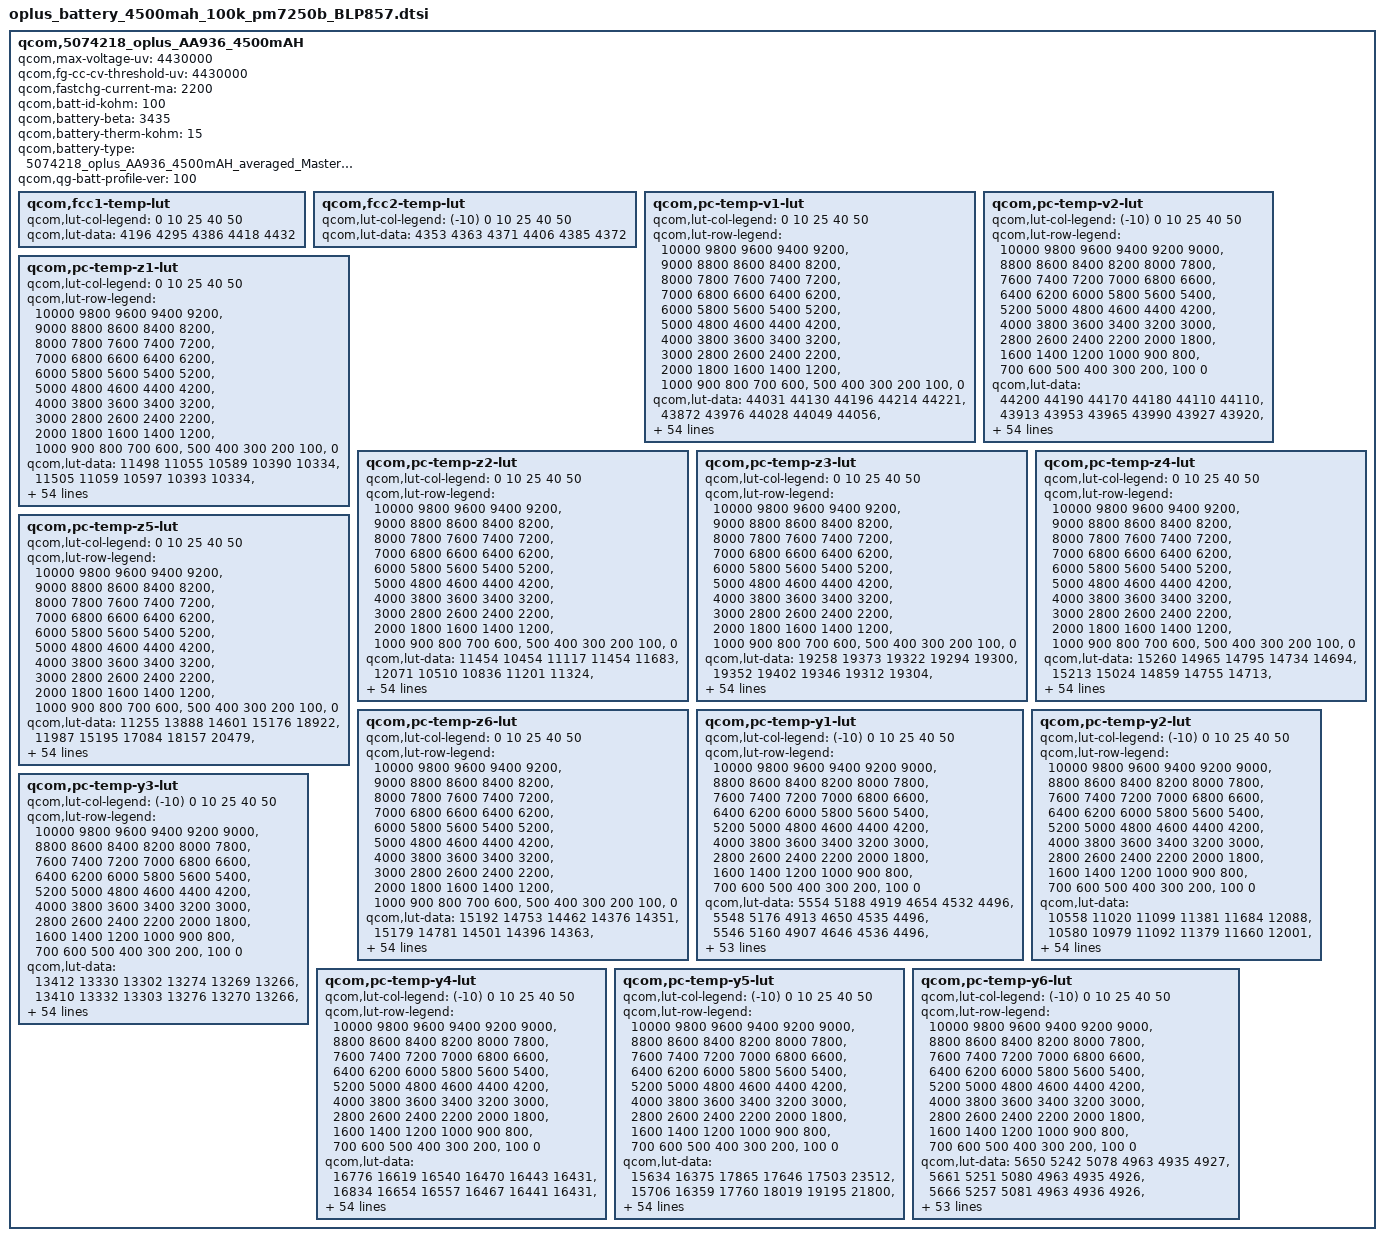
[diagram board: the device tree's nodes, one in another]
qcom,5074218_oplus_AA936_4500mAH {
    /* 5074218_oplus_AA936_4500mAH_averaged_MasterSlave_Mar5th2021 */
    qcom,max-voltage-uv = <4430000>;
    qcom,fg-cc-cv-threshold-uv = <4430000>;
    qcom,fastchg-current-ma = <2200>;
    qcom,batt-id-kohm = <100>;
    qcom,battery-beta = <3435>;
    qcom,battery-therm-kohm = <15>;
    qcom,battery-type = "5074218_oplus_AA936_4500mAH_averaged_MasterSlave_Mar5th2021";
    qcom,qg-batt-profile-ver = <100>;

	qcom,fcc1-temp-lut {
		qcom,lut-col-legend = <0 10 25 40 50>;
		qcom,lut-data = <4196 4295 4386 4418 4432>;
	};

	qcom,fcc2-temp-lut {
		qcom,lut-col-legend = <(-10) 0 10 25 40 50>;
		qcom,lut-data = <4353 4363 4371 4406 4385 4372>;
	};

	qcom,pc-temp-v1-lut {
		qcom,lut-col-legend = <0 10 25 40 50>;
		qcom,lut-row-legend = <10000 9800 9600 9400 9200>,
			<9000 8800 8600 8400 8200>,
			<8000 7800 7600 7400 7200>,
			<7000 6800 6600 6400 6200>,
			<6000 5800 5600 5400 5200>,
			<5000 4800 4600 4400 4200>,
			<4000 3800 3600 3400 3200>,
			<3000 2800 2600 2400 2200>,
			<2000 1800 1600 1400 1200>,
			<1000 900 800 700 600>,
			<500 400 300 200 100>,
			<0>;
		qcom,lut-data = <44031 44130 44196 44214 44221>,
			<43872 43976 44028 44049 44056>,
			<43684 43783 43848 43874 43882>,
			<43459 43580 43659 43688 43699>,
			<43216 43370 43459 43493 43507>,
			<42983 43150 43244 43285 43302>,
			<42753 42924 43017 43063 43084>,
			<42525 42691 42786 42835 42860>,
			<42300 42457 42549 42600 42629>,
			<42077 42224 42311 42361 42393>,
			<41858 41993 42075 42126 42159>,
			<41644 41767 41841 41891 41925>,
			<41433 41547 41614 41661 41695>,
			<41229 41334 41390 41434 41468>,
			<41031 41126 41173 41212 41244>,
			<40836 40924 40963 40997 41027>,
			<40643 40726 40759 40788 40815>,
			<40451 40541 40564 40587 40611>,
			<40246 40355 40385 40404 40425>,
			<40007 40132 40197 40220 40243>,
			<39765 39847 39961 40001 40031>,
			<39569 39584 39690 39737 39775>,
			<39400 39409 39462 39497 39534>,
			<39253 39270 39286 39310 39343>,
			<39131 39139 39133 39148 39176>,
			<39025 39010 38996 39005 39027>,
			<38928 38890 38873 38878 38895>,
			<38835 38782 38761 38762 38774>,
			<38748 38685 38656 38653 38661>,
			<38667 38595 38558 38552 38555>,
			<38593 38515 38469 38458 38457>,
			<38523 38443 38388 38371 38366>,
			<38463 38376 38314 38292 38282>,
			<38407 38314 38248 38221 38205>,
			<38356 38258 38188 38157 38134>,
			<38315 38208 38130 38088 38055>,
			<38273 38166 38078 38014 37961>,
			<38212 38112 38019 37933 37859>,
			<38115 38027 37937 37842 37758>,
			<37998 37918 37832 37740 37655>,
			<37874 37800 37718 37627 37541>,
			<37734 37665 37591 37499 37405>,
			<37565 37511 37449 37357 37258>,
			<37389 37334 37278 37188 37094>,
			<37294 37192 37145 37069 36982>,
			<37210 37121 37078 37011 36931>,
			<37179 37095 37060 36994 36915>,
			<37151 37076 37041 36978 36900>,
			<37108 37050 37007 36948 36863>,
			<36976 36932 36864 36764 36667>,
			<36619 36578 36485 36391 36294>,
			<36133 36103 36005 35907 35824>,
			<35518 35495 35385 35290 35215>,
			<34684 34674 34542 34447 34387>,
			<33359 33377 33219 33129 33105>,
			<30000 30000 30000 30000 30000>;
	};

	qcom,pc-temp-v2-lut {
		qcom,lut-col-legend = <(-10) 0 10 25 40 50>;
		qcom,lut-row-legend = <10000 9800 9600 9400 9200 9000>,
			<8800 8600 8400 8200 8000 7800>,
			<7600 7400 7200 7000 6800 6600>,
			<6400 6200 6000 5800 5600 5400>,
			<5200 5000 4800 4600 4400 4200>,
			<4000 3800 3600 3400 3200 3000>,
			<2800 2600 2400 2200 2000 1800>,
			<1600 1400 1200 1000 900 800>,
			<700 600 500 400 300 200>,
			<100 0>;
		qcom,lut-data = <44200 44190 44170 44180 44110 44110>,
			<43913 43953 43965 43990 43927 43920>,
			<43641 43723 43760 43795 43736 43725>,
			<43384 43500 43555 43596 43539 43525>,
			<43144 43287 43350 43393 43334 43320>,
			<42907 43071 43139 43183 43121 43108>,
			<42664 42844 42916 42958 42896 42886>,
			<42420 42609 42684 42722 42662 42655>,
			<42180 42376 42451 42487 42429 42424>,
			<41948 42141 42213 42249 42193 42189>,
			<41719 41909 41977 42012 41959 41956>,
			<41489 41680 41746 41778 41728 41726>,
			<41258 41455 41520 41547 41500 41498>,
			<41047 41237 41297 41321 41276 41275>,
			<40878 41026 41077 41100 41057 41057>,
			<40712 40822 40862 40886 40844 40845>,
			<40483 40621 40656 40679 40640 40641>,
			<40164 40428 40460 40478 40443 40446>,
			<39851 40217 40252 40275 40244 40249>,
			<39597 39943 40002 40067 40035 40043>,
			<39366 39641 39736 39851 39820 39832>,
			<39155 39389 39497 39614 39593 39610>,
			<38960 39175 39273 39348 39343 39364>,
			<38783 38989 39076 39125 39126 39145>,
			<38621 38829 38918 38966 38970 38987>,
			<38473 38688 38782 38835 38842 38857>,
			<38352 38560 38656 38710 38721 38736>,
			<38255 38445 38538 38595 38607 38620>,
			<38173 38337 38428 38487 38501 38513>,
			<38105 38234 38326 38386 38401 38412>,
			<38047 38136 38231 38292 38309 38318>,
			<37993 38049 38143 38206 38223 38230>,
			<37942 37975 38060 38130 38148 38155>,
			<37891 37910 37981 38054 38072 38078>,
			<37837 37859 37908 37970 37973 37972>,
			<37782 37819 37842 37882 37855 37827>,
			<37719 37775 37772 37788 37739 37688>,
			<37643 37714 37693 37685 37631 37575>,
			<37555 37639 37608 37580 37528 37471>,
			<37456 37548 37515 37483 37424 37365>,
			<37342 37434 37413 37389 37324 37265>,
			<37215 37300 37298 37282 37214 37155>,
			<37069 37141 37148 37136 37059 37002>,
			<36908 36969 36994 37010 36922 36851>,
			<36798 36866 36916 36925 36873 36800>,
			<36714 36792 36862 36886 36839 36769>,
			<36676 36762 36839 36870 36821 36754>,
			<36631 36724 36807 36841 36793 36729>,
			<36556 36653 36739 36782 36712 36653>,
			<36363 36474 36555 36580 36457 36412>,
			<36001 36102 36158 36165 36024 35989>,
			<35488 35575 35630 35628 35473 35461>,
			<34808 34891 34944 34931 34747 34772>,
			<33870 33943 34012 33971 33699 33831>,
			<32379 32444 32627 32503 32554 32456>,
			<29037 29258 29610 29012 29009 29565>;
	};

	qcom,pc-temp-z1-lut {
		qcom,lut-col-legend = <0 10 25 40 50>;
		qcom,lut-row-legend = <10000 9800 9600 9400 9200>,
			<9000 8800 8600 8400 8200>,
			<8000 7800 7600 7400 7200>,
			<7000 6800 6600 6400 6200>,
			<6000 5800 5600 5400 5200>,
			<5000 4800 4600 4400 4200>,
			<4000 3800 3600 3400 3200>,
			<3000 2800 2600 2400 2200>,
			<2000 1800 1600 1400 1200>,
			<1000 900 800 700 600>,
			<500 400 300 200 100>,
			<0>;
		qcom,lut-data = <11498 11055 10589 10390 10334>,
			<11505 11059 10597 10393 10334>,
			<11503 11038 10594 10393 10335>,
			<11484 11024 10583 10389 10334>,
			<11457 11019 10572 10385 10334>,
			<11436 11015 10561 10383 10334>,
			<11414 11005 10551 10380 10332>,
			<11396 10981 10545 10378 10331>,
			<11384 10959 10541 10376 10330>,
			<11374 10943 10538 10374 10329>,
			<11364 10926 10534 10372 10329>,
			<11340 10921 10531 10371 10328>,
			<11315 10923 10529 10370 10327>,
			<11312 10925 10526 10369 10327>,
			<11323 10925 10524 10368 10327>,
			<11330 10924 10523 10368 10327>,
			<11327 10922 10521 10368 10327>,
			<11320 10919 10521 10368 10327>,
			<11317 10915 10520 10368 10328>,
			<11311 10911 10520 10367 10328>,
			<11302 10903 10521 10367 10328>,
			<11299 10898 10522 10368 10329>,
			<11299 10901 10524 10369 10330>,
			<11301 10910 10525 10371 10331>,
			<11306 10917 10527 10372 10333>,
			<11312 10921 10530 10374 10334>,
			<11316 10925 10535 10375 10335>,
			<11318 10924 10539 10377 10336>,
			<11320 10920 10543 10379 10338>,
			<11317 10918 10546 10381 10339>,
			<11310 10922 10549 10384 10341>,
			<11304 10929 10551 10386 10342>,
			<11309 10932 10554 10389 10343>,
			<11325 10933 10560 10392 10345>,
			<11338 10934 10568 10395 10347>,
			<11346 10938 10574 10398 10350>,
			<11356 10949 10578 10402 10352>,
			<11363 10957 10582 10405 10353>,
			<11367 10961 10586 10407 10355>,
			<11370 10965 10591 10409 10356>,
			<11377 10971 10594 10410 10357>,
			<11386 10980 10595 10412 10358>,
			<11398 10987 10597 10413 10358>,
			<11417 11000 10602 10413 10359>,
			<11402 11000 10609 10414 10359>,
			<11395 11005 10607 10415 10360>,
			<11396 10997 10614 10416 10360>,
			<11394 10993 10614 10417 10360>,
			<11397 10999 10616 10418 10361>,
			<11401 11015 10626 10421 10362>,
			<11402 11023 10631 10422 10363>,
			<11420 11020 10631 10425 10366>,
			<11440 11049 10641 10429 10369>,
			<11454 11045 10643 10433 10371>,
			<11454 11045 10643 10433 10371>,
			<11454 11045 10643 10433 10371>;
	};

	qcom,pc-temp-z2-lut {
		qcom,lut-col-legend = <0 10 25 40 50>;
		qcom,lut-row-legend = <10000 9800 9600 9400 9200>,
			<9000 8800 8600 8400 8200>,
			<8000 7800 7600 7400 7200>,
			<7000 6800 6600 6400 6200>,
			<6000 5800 5600 5400 5200>,
			<5000 4800 4600 4400 4200>,
			<4000 3800 3600 3400 3200>,
			<3000 2800 2600 2400 2200>,
			<2000 1800 1600 1400 1200>,
			<1000 900 800 700 600>,
			<500 400 300 200 100>,
			<0>;
		qcom,lut-data = <11454 10454 11117 11454 11683>,
			<12071 10510 10836 11201 11324>,
			<12190 10523 10800 11046 11159>,
			<11438 10527 10802 10941 11109>,
			<10529 10516 10799 10881 11080>,
			<10351 10498 10762 10871 11068>,
			<10332 10477 10721 10865 11061>,
			<10320 10450 10716 10866 11059>,
			<10308 10433 10722 10903 11075>,
			<10297 10443 10727 10940 11094>,
			<10294 10466 10728 10937 11092>,
			<10304 10476 10731 10920 11083>,
			<10321 10477 10737 10912 11081>,
			<10334 10478 10746 10935 11103>,
			<10346 10480 10753 10963 11131>,
			<10357 10485 10755 10963 11134>,
			<10364 10491 10756 10949 11134>,
			<10370 10497 10753 10942 11140>,
			<10379 10503 10747 10954 11186>,
			<10403 10503 10743 10972 11252>,
			<10428 10493 10749 10982 11261>,
			<10426 10485 10768 10995 11205>,
			<10382 10494 10788 11002 11130>,
			<10346 10519 10815 10927 11023>,
			<10350 10529 10839 10800 10893>,
			<10364 10523 10825 10764 10856>,
			<10371 10515 10765 10758 10855>,
			<10370 10512 10727 10758 10858>,
			<10368 10506 10722 10779 10883>,
			<10369 10502 10722 10824 10940>,
			<10382 10509 10728 10856 10988>,
			<10397 10525 10751 10875 11032>,
			<10406 10541 10778 10895 11083>,
			<10413 10557 10810 10933 11150>,
			<10418 10570 10845 10986 11231>,
			<10420 10571 10863 11025 11294>,
			<10421 10571 10872 11049 11346>,
			<10425 10571 10881 11072 11379>,
			<10440 10588 10913 11107 11371>,
			<10453 10611 10966 11150 11329>,
			<10443 10610 10983 11166 11288>,
			<10416 10579 10940 11127 11254>,
			<10414 10570 10903 11092 11216>,
			<10428 10581 10887 11093 11163>,
			<10581 10652 10912 11100 11159>,
			<16059 10636 10876 11049 11222>,
			<17859 10621 10851 11117 11237>,
			<19549 10621 10867 11154 11338>,
			<19078 10630 10847 11182 11456>,
			<17840 10688 10889 10971 11065>,
			<16435 10733 10815 10859 10996>,
			<16866 10722 10750 10817 10927>,
			<15900 10683 10721 10782 10851>,
			<14515 10805 10649 10723 10782>,
			<14515 10805 10649 10723 10782>,
			<14515 10805 10649 10723 10782>;
	};

	qcom,pc-temp-z3-lut {
		qcom,lut-col-legend = <0 10 25 40 50>;
		qcom,lut-row-legend = <10000 9800 9600 9400 9200>,
			<9000 8800 8600 8400 8200>,
			<8000 7800 7600 7400 7200>,
			<7000 6800 6600 6400 6200>,
			<6000 5800 5600 5400 5200>,
			<5000 4800 4600 4400 4200>,
			<4000 3800 3600 3400 3200>,
			<3000 2800 2600 2400 2200>,
			<2000 1800 1600 1400 1200>,
			<1000 900 800 700 600>,
			<500 400 300 200 100>,
			<0>;
		qcom,lut-data = <19258 19373 19322 19294 19300>,
			<19352 19402 19346 19312 19304>,
			<19431 19441 19360 19322 19308>,
			<19508 19464 19370 19328 19314>,
			<19567 19474 19376 19331 19318>,
			<19584 19480 19381 19332 19318>,
			<19592 19481 19384 19332 19317>,
			<19595 19482 19383 19331 19316>,
			<19594 19482 19378 19331 19315>,
			<19590 19479 19373 19330 19314>,
			<19585 19473 19370 19328 19312>,
			<19578 19468 19367 19326 19309>,
			<19571 19463 19365 19324 19307>,
			<19566 19459 19361 19321 19306>,
			<19561 19456 19358 19319 19305>,
			<19559 19454 19356 19318 19304>,
			<19558 19452 19354 19316 19304>,
			<19558 19449 19353 19315 19304>,
			<19558 19446 19352 19313 19300>,
			<19567 19447 19351 19312 19295>,
			<19579 19457 19350 19313 19296>,
			<19579 19466 19349 19319 19310>,
			<19567 19462 19350 19327 19321>,
			<19557 19450 19365 19333 19321>,
			<19558 19445 19383 19339 19320>,
			<19563 19458 19386 19340 19319>,
			<19565 19474 19386 19339 19317>,
			<19563 19476 19386 19337 19316>,
			<19561 19471 19382 19335 19314>,
			<19558 19465 19376 19332 19312>,
			<19555 19460 19372 19328 19310>,
			<19551 19455 19367 19325 19307>,
			<19548 19452 19364 19322 19305>,
			<19545 19450 19362 19319 19302>,
			<19543 19449 19361 19316 19299>,
			<19541 19449 19361 19316 19298>,
			<19539 19448 19360 19317 19301>,
			<19536 19448 19360 19318 19305>,
			<19531 19443 19360 19320 19307>,
			<19526 19436 19359 19324 19308>,
			<19522 19433 19358 19325 19309>,
			<19518 19431 19355 19323 19310>,
			<19514 19428 19353 19322 19310>,
			<19507 19423 19348 19324 19311>,
			<19271 19409 19342 19318 19309>,
			<19258 19401 19338 19311 19298>,
			<19257 19402 19333 19310 19294>,
			<19256 19399 19333 19306 19291>,
			<19256 19390 19333 19302 19292>,
			<19257 19386 19340 19320 19302>,
			<19257 19380 19349 19319 19304>,
			<19257 19377 19350 19323 19303>,
			<19257 19374 19353 19322 19304>,
			<19257 19339 19354 19323 19305>,
			<19257 19339 19354 19323 19305>,
			<19257 19339 19354 19323 19305>;
	};

	qcom,pc-temp-z4-lut {
		qcom,lut-col-legend = <0 10 25 40 50>;
		qcom,lut-row-legend = <10000 9800 9600 9400 9200>,
			<9000 8800 8600 8400 8200>,
			<8000 7800 7600 7400 7200>,
			<7000 6800 6600 6400 6200>,
			<6000 5800 5600 5400 5200>,
			<5000 4800 4600 4400 4200>,
			<4000 3800 3600 3400 3200>,
			<3000 2800 2600 2400 2200>,
			<2000 1800 1600 1400 1200>,
			<1000 900 800 700 600>,
			<500 400 300 200 100>,
			<0>;
		qcom,lut-data = <15260 14965 14795 14734 14694>,
			<15213 15024 14859 14755 14713>,
			<15172 15015 14855 14758 14718>,
			<15138 15000 14821 14742 14706>,
			<15104 14955 14788 14722 14689>,
			<15056 14891 14761 14706 14678>,
			<14989 14845 14737 14691 14667>,
			<14926 14807 14721 14681 14660>,
			<14883 14778 14710 14675 14656>,
			<14846 14758 14701 14670 14653>,
			<14817 14743 14695 14666 14650>,
			<14790 14736 14689 14661 14648>,
			<14770 14733 14685 14658 14645>,
			<14765 14731 14681 14653 14641>,
			<14763 14729 14677 14649 14637>,
			<14762 14726 14673 14645 14632>,
			<14764 14724 14670 14640 14627>,
			<14772 14726 14668 14637 14623>,
			<14784 14731 14667 14635 14623>,
			<14808 14744 14666 14634 14623>,
			<14837 14794 14690 14642 14626>,
			<14853 14836 14753 14681 14647>,
			<14867 14837 14780 14706 14663>,
			<14875 14834 14763 14701 14663>,
			<14867 14829 14738 14690 14662>,
			<14842 14803 14722 14682 14661>,
			<14823 14771 14709 14675 14657>,
			<14812 14761 14701 14669 14652>,
			<14805 14756 14696 14663 14647>,
			<14803 14754 14692 14659 14643>,
			<14803 14754 14691 14656 14640>,
			<14803 14753 14689 14653 14637>,
			<14803 14754 14689 14651 14635>,
			<14804 14756 14690 14651 14634>,
			<14804 14758 14692 14651 14633>,
			<14800 14758 14695 14652 14633>,
			<14793 14757 14700 14662 14641>,
			<14788 14755 14704 14672 14649>,
			<14783 14753 14704 14672 14649>,
			<14778 14748 14703 14668 14645>,
			<14766 14739 14702 14663 14642>,
			<14745 14722 14691 14657 14639>,
			<14725 14707 14680 14652 14637>,
			<14710 14694 14675 14648 14636>,
			<14879 14666 14659 14642 14628>,
			<14878 14648 14644 14633 14624>,
			<14872 14639 14636 14624 14618>,
			<14868 14636 14627 14619 14613>,
			<14865 14640 14625 14618 14610>,
			<14866 14648 14629 14616 14613>,
			<14870 14659 14622 14617 14615>,
			<14870 14661 14621 14615 14614>,
			<14873 14664 14619 14616 14614>,
			<14875 14704 14619 14616 14613>,
			<14875 14704 14619 14616 14613>,
			<14875 14704 14619 14616 14613>;
	};

	qcom,pc-temp-z5-lut {
		qcom,lut-col-legend = <0 10 25 40 50>;
		qcom,lut-row-legend = <10000 9800 9600 9400 9200>,
			<9000 8800 8600 8400 8200>,
			<8000 7800 7600 7400 7200>,
			<7000 6800 6600 6400 6200>,
			<6000 5800 5600 5400 5200>,
			<5000 4800 4600 4400 4200>,
			<4000 3800 3600 3400 3200>,
			<3000 2800 2600 2400 2200>,
			<2000 1800 1600 1400 1200>,
			<1000 900 800 700 600>,
			<500 400 300 200 100>,
			<0>;
		qcom,lut-data = <11255 13888 14601 15176 18922>,
			<11987 15195 17084 18157 20479>,
			<13299 17281 18149 19438 21673>,
			<15796 18924 18754 19837 22558>,
			<18715 19951 19293 20134 23280>,
			<20766 20842 20087 20577 23941>,
			<22330 21927 20848 21131 24555>,
			<23773 23217 21239 21658 25000>,
			<25196 24545 21718 22177 25327>,
			<26580 26046 21997 22620 25555>,
			<28142 27518 22286 22876 25462>,
			<30279 27971 22724 22993 24809>,
			<32273 27843 22856 23034 24429>,
			<33177 27687 22865 23093 24801>,
			<33564 27874 22910 23263 25588>,
			<34038 28614 23204 23753 27053>,
			<35460 29053 23794 24777 30274>,
			<37946 28865 24379 25627 32195>,
			<40007 28563 25097 26209 30715>,
			<41680 28894 25600 26638 27917>,
			<42925 32160 24393 25904 26137>,
			<42102 35081 21063 21989 24849>,
			<35861 32386 19642 19400 23669>,
			<30625 25129 20149 19629 22323>,
			<30800 21970 21099 20202 21062>,
			<32091 24993 22381 20948 20824>,
			<33493 29504 24385 22214 21589>,
			<35207 32227 26269 23584 22711>,
			<37193 34211 27718 24753 23915>,
			<38850 35647 29046 25917 25370>,
			<40433 36532 30370 27110 26708>,
			<41507 37200 31711 28403 28004>,
			<41816 37976 33068 29621 29074>,
			<41994 39068 34870 30755 29782>,
			<42054 39866 36692 31796 30340>,
			<41965 39945 37079 32027 30464>,
			<41787 39920 36435 30752 29438>,
			<41590 39833 35431 29440 28311>,
			<41285 38011 33992 29706 29050>,
			<40878 35402 32040 30834 32163>,
			<40234 34658 30871 31536 35226>,
			<39429 34640 30343 31649 38191>,
			<39684 34406 29864 31717 39666>,
			<40649 33397 26720 31903 38422>,
			<12724 37635 27436 28384 35259>,
			<11484 36636 30001 26928 25936>,
			<11407 40996 30121 32822 27431>,
			<11364 39265 35122 37309 32321>,
			<11369 28849 35350 32135 37563>,
			<11395 25471 30919 48674 42207>,
			<11402 21113 37695 40848 42573>,
			<11357 19868 37344 48817 38026>,
			<11309 18934 40980 44622 37177>,
			<11262 14302 39515 43387 36663>,
			<11262 14302 39515 43387 36663>,
			<11262 14302 39515 43387 36663>;
	};

	qcom,pc-temp-z6-lut {
		qcom,lut-col-legend = <0 10 25 40 50>;
		qcom,lut-row-legend = <10000 9800 9600 9400 9200>,
			<9000 8800 8600 8400 8200>,
			<8000 7800 7600 7400 7200>,
			<7000 6800 6600 6400 6200>,
			<6000 5800 5600 5400 5200>,
			<5000 4800 4600 4400 4200>,
			<4000 3800 3600 3400 3200>,
			<3000 2800 2600 2400 2200>,
			<2000 1800 1600 1400 1200>,
			<1000 900 800 700 600>,
			<500 400 300 200 100>,
			<0>;
		qcom,lut-data = <15192 14753 14462 14376 14351>,
			<15179 14781 14501 14396 14363>,
			<15164 14781 14501 14401 14367>,
			<15148 14778 14490 14397 14365>,
			<15127 14753 14479 14391 14361>,
			<15094 14714 14468 14384 14356>,
			<15039 14685 14458 14377 14351>,
			<14984 14659 14448 14372 14347>,
			<14942 14637 14439 14369 14344>,
			<14905 14621 14432 14366 14342>,
			<14874 14608 14427 14363 14340>,
			<14845 14599 14422 14359 14337>,
			<14823 14593 14418 14356 14335>,
			<14814 14588 14414 14353 14332>,
			<14809 14585 14411 14349 14330>,
			<14807 14581 14408 14347 14327>,
			<14807 14579 14405 14344 14325>,
			<14808 14578 14403 14342 14323>,
			<14810 14577 14402 14340 14320>,
			<14822 14580 14401 14339 14318>,
			<14839 14607 14411 14343 14320>,
			<14844 14630 14439 14365 14338>,
			<14845 14630 14450 14379 14351>,
			<14844 14624 14450 14379 14351>,
			<14841 14620 14450 14378 14351>,
			<14835 14616 14449 14377 14350>,
			<14830 14613 14444 14374 14347>,
			<14826 14609 14439 14370 14344>,
			<14823 14606 14435 14366 14342>,
			<14823 14603 14431 14363 14339>,
			<14823 14602 14429 14360 14336>,
			<14823 14601 14426 14357 14334>,
			<14823 14600 14425 14355 14331>,
			<14825 14602 14425 14354 14329>,
			<14826 14605 14427 14353 14327>,
			<14828 14607 14428 14353 14327>,
			<14829 14610 14432 14358 14333>,
			<14831 14611 14435 14364 14338>,
			<14834 14611 14435 14364 14339>,
			<14836 14610 14435 14365 14338>,
			<14835 14608 14435 14365 14338>,
			<14833 14603 14430 14361 14337>,
			<14833 14600 14425 14358 14336>,
			<14835 14597 14421 14358 14337>,
			<14805 14585 14412 14353 14333>,
			<14802 14575 14404 14345 14325>,
			<14801 14574 14399 14340 14320>,
			<14802 14572 14396 14336 14316>,
			<14807 14572 14396 14334 14315>,
			<14815 14579 14402 14344 14323>,
			<14823 14585 14406 14344 14325>,
			<14830 14588 14407 14346 14325>,
			<14839 14593 14409 14347 14326>,
			<14853 14598 14411 14348 14327>,
			<14853 14598 14411 14348 14327>,
			<14853 14598 14411 14348 14327>;
	};

	qcom,pc-temp-y1-lut {
		qcom,lut-col-legend = <(-10) 0 10 25 40 50>;
		qcom,lut-row-legend = <10000 9800 9600 9400 9200 9000>,
			<8800 8600 8400 8200 8000 7800>,
			<7600 7400 7200 7000 6800 6600>,
			<6400 6200 6000 5800 5600 5400>,
			<5200 5000 4800 4600 4400 4200>,
			<4000 3800 3600 3400 3200 3000>,
			<2800 2600 2400 2200 2000 1800>,
			<1600 1400 1200 1000 900 800>,
			<700 600 500 400 300 200>,
			<100 0>;
		qcom,lut-data = <5554 5188 4919 4654 4532 4496>,
			<5548 5176 4913 4650 4535 4496>,
			<5546 5160 4907 4646 4536 4496>,
			<5546 5144 4901 4643 4536 4496>,
			<5548 5131 4895 4639 4535 4496>,
			<5549 5125 4891 4636 4534 4496>,
			<5550 5126 4887 4632 4531 4496>,
			<5554 5130 4884 4629 4527 4496>,
			<5554 5131 4881 4626 4524 4496>,
			<5553 5129 4877 4621 4522 4495>,
			<5552 5126 4872 4617 4521 4493>,
			<5550 5125 4869 4615 4519 4493>,
			<5546 5122 4865 4613 4518 4493>,
			<5544 5121 4863 4612 4517 4493>,
			<5543 5122 4860 4611 4516 4493>,
			<5542 5122 4857 4610 4516 4492>,
			<5543 5121 4856 4609 4515 4491>,
			<5545 5119 4855 4608 4515 4491>,
			<5547 5118 4855 4608 4514 4490>,
			<5547 5121 4855 4608 4514 4490>,
			<5547 5125 4854 4608 4514 4489>,
			<5548 5125 4854 4608 4514 4489>,
			<5554 5123 4855 4609 4513 4490>,
			<5560 5120 4856 4611 4513 4492>,
			<5559 5119 4856 4612 4514 4492>,
			<5557 5118 4857 4614 4517 4493>,
			<5555 5118 4858 4615 4518 4493>,
			<5554 5124 4861 4616 4518 4493>,
			<5553 5132 4864 4617 4517 4493>,
			<5553 5133 4864 4620 4518 4493>,
			<5552 5133 4865 4623 4519 4494>,
			<5552 5133 4865 4625 4520 4494>,
			<5552 5133 4868 4626 4521 4496>,
			<5550 5134 4873 4627 4523 4498>,
			<5546 5134 4875 4629 4525 4499>,
			<5540 5135 4876 4631 4527 4499>,
			<5535 5137 4878 4634 4529 4499>,
			<5534 5142 4879 4637 4530 4500>,
			<5534 5151 4881 4640 4531 4502>,
			<5535 5154 4882 4642 4532 4503>,
			<5533 5148 4883 4643 4533 4502>,
			<5532 5142 4884 4645 4534 4501>,
			<5534 5143 4887 4647 4534 4502>,
			<5542 5147 4892 4648 4535 4504>,
			<5548 5149 4897 4650 4535 4505>,
			<5552 5151 4902 4653 4536 4505>,
			<5549 5157 4905 4654 4536 4506>,
			<5543 5159 4902 4652 4538 4507>,
			<5540 5155 4904 4655 4538 4507>,
			<5555 5156 4915 4653 4538 4506>,
			<5556 5155 4913 4655 4539 4507>,
			<5563 5150 4919 4658 4541 4510>,
			<5574 5162 4924 4662 4542 4508>,
			<5592 5161 4941 4664 4544 4512>,
			<5592 5161 4941 4664 4544 4512>,
			<5592 5161 4941 4664 4544 4512>;
	};

	qcom,pc-temp-y2-lut {
		qcom,lut-col-legend = <(-10) 0 10 25 40 50>;
		qcom,lut-row-legend = <10000 9800 9600 9400 9200 9000>,
			<8800 8600 8400 8200 8000 7800>,
			<7600 7400 7200 7000 6800 6600>,
			<6400 6200 6000 5800 5600 5400>,
			<5200 5000 4800 4600 4400 4200>,
			<4000 3800 3600 3400 3200 3000>,
			<2800 2600 2400 2200 2000 1800>,
			<1600 1400 1200 1000 900 800>,
			<700 600 500 400 300 200>,
			<100 0>;
		qcom,lut-data = <10558 11020 11099 11381 11684 12088>,
			<10580 10979 11092 11379 11660 12001>,
			<10607 10931 11081 11377 11626 11906>,
			<10634 10885 11069 11376 11590 11815>,
			<10655 10850 11057 11375 11558 11737>,
			<10666 10833 11048 11374 11537 11682>,
			<10664 10837 11039 11375 11529 11650>,
			<10660 10849 11030 11376 11522 11627>,
			<10659 10857 11028 11375 11510 11612>,
			<10671 10859 11037 11367 11474 11588>,
			<10690 10860 11046 11361 11441 11565>,
			<10708 10866 11047 11349 11442 11559>,
			<10732 10875 11045 11321 11468 11564>,
			<10757 10889 11045 11306 11481 11568>,
			<10804 10919 11051 11303 11475 11561>,
			<10851 10961 11064 11302 11469 11546>,
			<10852 11008 11091 11314 11476 11534>,
			<10815 11071 11158 11351 11496 11524>,
			<10784 11106 11197 11372 11517 11520>,
			<10776 11072 11177 11395 11533 11528>,
			<10772 11012 11143 11424 11552 11557>,
			<10771 10997 11139 11443 11582 11633>,
			<10776 11006 11171 11490 11641 11871>,
			<10780 11019 11205 11522 11703 12050>,
			<10593 11038 11223 11533 11758 12037>,
			<10070 11072 11236 11547 11815 11993>,
			<9808 11090 11250 11566 11853 11975>,
			<9784 11096 11269 11601 11869 11988>,
			<9774 11100 11282 11624 11871 12011>,
			<9761 11101 11282 11595 11876 12044>,
			<9742 11099 11276 11539 11891 12100>,
			<9724 11101 11270 11528 11901 12134>,
			<9711 11116 11259 11568 11916 12135>,
			<9699 11133 11246 11604 11930 12125>,
			<9691 11132 11241 11593 11925 12134>,
			<9685 11097 11231 11562 11900 12202>,
			<9680 11049 11224 11548 11879 12252>,
			<9676 10997 11243 11559 11869 12234>,
			<9672 10932 11278 11571 11865 12195>,
			<9669 10857 11285 11580 11861 12163>,
			<9667 10777 11250 11601 11834 12117>,
			<9664 10668 11205 11612 11806 12077>,
			<9662 10452 11156 11639 11794 12060>,
			<9661 10136 11082 11667 11790 12056>,
			<9660 9926 10987 11650 11764 12017>,
			<9659 9788 10915 11616 11748 11876>,
			<9658 9748 10890 11578 11718 11701>,
			<9657 9725 10853 11563 11592 11636>,
			<9657 9711 10831 11504 11530 11603>,
			<9656 9697 10809 11424 11566 11596>,
			<9655 9686 10740 11383 11558 11556>,
			<9655 9675 10656 11330 11472 11487>,
			<9653 9666 10567 11280 11362 11432>,
			<9651 9661 10550 11105 11170 11322>,
			<9651 9661 10550 11105 11170 11322>,
			<9651 9661 10550 11105 11170 11322>;
	};

	qcom,pc-temp-y3-lut {
		qcom,lut-col-legend = <(-10) 0 10 25 40 50>;
		qcom,lut-row-legend = <10000 9800 9600 9400 9200 9000>,
			<8800 8600 8400 8200 8000 7800>,
			<7600 7400 7200 7000 6800 6600>,
			<6400 6200 6000 5800 5600 5400>,
			<5200 5000 4800 4600 4400 4200>,
			<4000 3800 3600 3400 3200 3000>,
			<2800 2600 2400 2200 2000 1800>,
			<1600 1400 1200 1000 900 800>,
			<700 600 500 400 300 200>,
			<100 0>;
		qcom,lut-data = <13412 13330 13302 13274 13269 13266>,
			<13410 13332 13303 13276 13270 13266>,
			<13410 13334 13304 13278 13271 13267>,
			<13410 13336 13305 13279 13272 13267>,
			<13411 13338 13306 13280 13273 13267>,
			<13412 13339 13308 13280 13273 13268>,
			<13414 13341 13309 13280 13273 13269>,
			<13416 13342 13310 13279 13273 13270>,
			<13418 13343 13310 13279 13273 13270>,
			<13420 13345 13309 13280 13273 13271>,
			<13423 13347 13309 13281 13274 13271>,
			<13421 13348 13309 13280 13274 13271>,
			<13416 13349 13311 13280 13273 13271>,
			<13409 13350 13312 13280 13273 13271>,
			<13405 13350 13312 13282 13273 13271>,
			<13400 13351 13311 13284 13273 13271>,
			<13394 13349 13311 13284 13273 13271>,
			<13386 13345 13312 13285 13274 13271>,
			<13379 13340 13312 13285 13274 13271>,
			<13373 13334 13310 13286 13275 13272>,
			<13368 13327 13305 13287 13277 13273>,
			<13363 13323 13301 13286 13276 13273>,
			<13360 13320 13298 13281 13273 13270>,
			<13356 13317 13297 13277 13270 13268>,
			<13346 13315 13296 13278 13270 13268>,
			<13327 13314 13296 13278 13270 13267>,
			<13310 13313 13295 13278 13271 13267>,
			<13291 13313 13295 13278 13270 13268>,
			<13277 13313 13294 13278 13270 13268>,
			<13277 13312 13294 13278 13270 13268>,
			<13288 13308 13294 13277 13270 13268>,
			<13300 13304 13293 13277 13269 13268>,
			<13311 13302 13293 13278 13269 13268>,
			<13323 13300 13292 13278 13269 13268>,
			<13338 13301 13291 13278 13269 13268>,
			<13356 13307 13291 13277 13269 13267>,
			<13378 13313 13291 13276 13269 13267>,
			<13402 13314 13290 13276 13270 13267>,
			<13432 13316 13288 13276 13270 13267>,
			<13468 13317 13288 13276 13270 13268>,
			<13517 13321 13288 13276 13270 13268>,
			<13576 13325 13289 13276 13270 13268>,
			<13643 13328 13291 13275 13271 13267>,
			<13723 13331 13295 13275 13271 13265>,
			<13829 13343 13298 13275 13271 13266>,
			<13972 13366 13302 13277 13272 13267>,
			<14063 13383 13306 13277 13273 13268>,
			<14157 13396 13307 13276 13273 13269>,
			<14250 13406 13309 13280 13273 13270>,
			<14384 13438 13314 13279 13273 13269>,
			<14567 13477 13316 13279 13273 13268>,
			<14864 13535 13323 13279 13273 13269>,
			<15432 13658 13333 13280 13272 13269>,
			<17263 13898 13357 13282 13273 13269>,
			<17263 13898 13357 13282 13273 13269>,
			<17263 13898 13357 13282 13273 13269>;
	};

	qcom,pc-temp-y4-lut {
		qcom,lut-col-legend = <(-10) 0 10 25 40 50>;
		qcom,lut-row-legend = <10000 9800 9600 9400 9200 9000>,
			<8800 8600 8400 8200 8000 7800>,
			<7600 7400 7200 7000 6800 6600>,
			<6400 6200 6000 5800 5600 5400>,
			<5200 5000 4800 4600 4400 4200>,
			<4000 3800 3600 3400 3200 3000>,
			<2800 2600 2400 2200 2000 1800>,
			<1600 1400 1200 1000 900 800>,
			<700 600 500 400 300 200>,
			<100 0>;
		qcom,lut-data = <16776 16619 16540 16470 16443 16431>,
			<16834 16654 16557 16467 16441 16431>,
			<16913 16694 16569 16466 16439 16430>,
			<16994 16732 16578 16465 16438 16430>,
			<17060 16761 16583 16465 16437 16429>,
			<17092 16775 16585 16465 16436 16429>,
			<17086 16771 16583 16466 16436 16429>,
			<17071 16761 16576 16468 16437 16428>,
			<17066 16754 16573 16469 16438 16428>,
			<17069 16748 16571 16470 16439 16429>,
			<17077 16743 16570 16472 16440 16429>,
			<17090 16746 16573 16476 16442 16431>,
			<17119 16759 16580 16482 16446 16432>,
			<17165 16777 16590 16488 16450 16435>,
			<17307 16808 16604 16494 16454 16437>,
			<17469 16853 16625 16500 16459 16441>,
			<17463 16918 16663 16511 16465 16445>,
			<17257 17024 16735 16528 16474 16452>,
			<17053 17084 16776 16549 16484 16459>,
			<16953 16994 16750 16585 16501 16469>,
			<16876 16814 16694 16619 16518 16478>,
			<16806 16707 16638 16603 16514 16477>,
			<16732 16643 16569 16519 16475 16453>,
			<16684 16601 16522 16466 16445 16434>,
			<16680 16583 16514 16462 16443 16433>,
			<16683 16570 16510 16460 16442 16433>,
			<16687 16562 16508 16460 16442 16434>,
			<16700 16557 16508 16461 16443 16435>,
			<16714 16553 16508 16464 16446 16436>,
			<16718 16547 16509 16467 16449 16437>,
			<16715 16540 16512 16473 16453 16440>,
			<16711 16533 16514 16480 16458 16444>,
			<16714 16528 16515 16492 16466 16450>,
			<16719 16524 16515 16500 16472 16456>,
			<16725 16525 16514 16496 16468 16454>,
			<16735 16536 16509 16485 16454 16442>,
			<16743 16550 16502 16473 16444 16434>,
			<16747 16560 16487 16461 16442 16432>,
			<16750 16571 16470 16450 16440 16431>,
			<16751 16581 16467 16446 16439 16431>,
			<16751 16590 16475 16442 16438 16431>,
			<16752 16601 16487 16441 16437 16431>,
			<16754 16615 16499 16442 16434 16429>,
			<16757 16632 16514 16442 16431 16426>,
			<16771 16654 16539 16444 16434 16427>,
			<16816 16689 16577 16452 16438 16431>,
			<16862 16721 16606 16459 16441 16439>,
			<16911 16754 16615 16462 16450 16453>,
			<16943 16782 16622 16466 16457 16458>,
			<16981 16812 16644 16465 16444 16437>,
			<16989 16835 16659 16463 16441 16435>,
			<17037 16874 16701 16472 16450 16445>,
			<17187 16955 16766 16504 16463 16456>,
			<18376 17143 16915 16586 16534 16503>,
			<18376 17143 16915 16586 16534 16503>,
			<18376 17143 16915 16586 16534 16503>;
	};

	qcom,pc-temp-y5-lut {
		qcom,lut-col-legend = <(-10) 0 10 25 40 50>;
		qcom,lut-row-legend = <10000 9800 9600 9400 9200 9000>,
			<8800 8600 8400 8200 8000 7800>,
			<7600 7400 7200 7000 6800 6600>,
			<6400 6200 6000 5800 5600 5400>,
			<5200 5000 4800 4600 4400 4200>,
			<4000 3800 3600 3400 3200 3000>,
			<2800 2600 2400 2200 2000 1800>,
			<1600 1400 1200 1000 900 800>,
			<700 600 500 400 300 200>,
			<100 0>;
		qcom,lut-data = <15634 16375 17865 17646 17503 23512>,
			<15706 16359 17760 18019 19195 21800>,
			<15769 16342 17566 18016 20356 20672>,
			<15825 16327 17344 17789 21045 20090>,
			<15876 16315 17157 17492 21323 20016>,
			<15922 16310 17064 17277 21250 20413>,
			<15971 16312 17069 16813 20593 21628>,
			<16008 16318 17083 15999 19522 23357>,
			<15990 16318 17049 15692 19049 24043>,
			<15841 16278 16476 15619 18947 23990>,
			<15579 16205 15829 15502 18848 23719>,
			<15042 16022 15648 15146 18434 23094>,
			<14041 15580 15562 14579 17522 21843>,
			<13554 15136 15449 14388 16740 20647>,
			<14055 14556 14980 14674 16153 19394>,
			<14883 14024 14424 14980 15679 18207>,
			<15388 14052 14263 14906 15369 17508>,
			<15715 14672 14189 14592 15119 16869>,
			<16024 15413 14159 14459 15023 16570>,
			<16452 16198 15113 15371 15884 17152>,
			<16877 16973 16791 16636 17262 18282>,
			<16988 17226 17514 17098 17820 19082>,
			<16938 17289 17764 17295 18052 19694>,
			<16834 17319 17970 17558 18280 20159>,
			<15791 17314 18265 18273 19021 20469>,
			<13123 17292 18578 19169 20140 20703>,
			<11615 17301 18718 19672 20470 20803>,
			<11218 17603 18604 20077 20175 20803>,
			<10994 17936 18444 20225 19764 20755>,
			<10973 17678 18439 19673 19199 20451>,
			<11111 16547 18496 18780 18280 19579>,
			<11241 15585 18488 18604 17773 19042>,
			<11343 15005 18299 19199 17566 18832>,
			<11489 14592 18091 19706 17452 18717>,
			<11652 14841 18231 19669 17714 18945>,
			<11875 16598 19040 19545 18771 19548>,
			<12017 17890 19578 19606 19839 20267>,
			<12007 17706 18866 21121 20783 21295>,
			<11973 17319 17520 22791 21615 22419>,
			<11954 17171 16858 22930 22015 22933>,
			<11953 17122 16646 22274 22189 23300>,
			<11950 17034 16616 21826 22469 23511>,
			<11831 16415 17025 20337 25186 22467>,
			<11540 15106 17544 19313 28246 20236>,
			<11479 14520 17195 20177 24859 19072>,
			<11477 14070 16394 19926 23200 19547>,
			<11486 13713 15872 18995 24226 22226>,
			<11512 13240 15532 17348 22637 22296>,
			<11726 12743 15774 19337 22230 22405>,
			<11673 13183 16543 20588 26581 24695>,
			<11777 13723 16600 20670 27313 24904>,
			<11747 13458 16468 20040 24545 26585>,
			<11504 13247 15956 19464 21050 22877>,
			<10318 12701 15765 18547 19080 19370>,
			<10318 12701 15765 18547 19080 19370>,
			<10318 12701 15765 18547 19080 19370>;
	};

	qcom,pc-temp-y6-lut {
		qcom,lut-col-legend = <(-10) 0 10 25 40 50>;
		qcom,lut-row-legend = <10000 9800 9600 9400 9200 9000>,
			<8800 8600 8400 8200 8000 7800>,
			<7600 7400 7200 7000 6800 6600>,
			<6400 6200 6000 5800 5600 5400>,
			<5200 5000 4800 4600 4400 4200>,
			<4000 3800 3600 3400 3200 3000>,
			<2800 2600 2400 2200 2000 1800>,
			<1600 1400 1200 1000 900 800>,
			<700 600 500 400 300 200>,
			<100 0>;
		qcom,lut-data = <5650 5242 5078 4963 4935 4927>,
			<5661 5251 5080 4963 4935 4926>,
			<5666 5257 5081 4963 4936 4926>,
			<5666 5259 5080 4963 4936 4926>,
			<5663 5259 5079 4963 4936 4926>,
			<5659 5258 5077 4963 4936 4927>,
			<5650 5254 5074 4962 4936 4927>,
			<5636 5247 5070 4962 4936 4928>,
			<5627 5241 5066 4962 4935 4928>,
			<5622 5235 5063 4962 4936 4929>,
			<5619 5231 5060 4963 4937 4929>,
			<5618 5231 5060 4964 4937 4929>,
			<5618 5232 5061 4965 4938 4930>,
			<5620 5234 5063 4966 4939 4930>,
			<5651 5241 5066 4968 4940 4931>,
			<5694 5252 5071 4971 4941 4932>,
			<5691 5267 5080 4975 4943 4933>,
			<5630 5292 5100 4980 4946 4935>,
			<5570 5307 5112 4986 4950 4937>,
			<5539 5278 5103 4997 4955 4941>,
			<5516 5222 5083 5007 4961 4944>,
			<5497 5188 5064 5002 4959 4944>,
			<5482 5168 5042 4974 4945 4935>,
			<5470 5156 5028 4957 4934 4927>,
			<5462 5151 5026 4956 4934 4927>,
			<5455 5148 5025 4956 4934 4927>,
			<5453 5148 5025 4956 4934 4927>,
			<5459 5149 5025 4957 4935 4927>,
			<5470 5150 5026 4958 4935 4928>,
			<5483 5150 5027 4959 4936 4928>,
			<5500 5148 5029 4960 4937 4929>,
			<5520 5148 5030 4962 4938 4930>,
			<5542 5149 5031 4966 4941 4932>,
			<5567 5151 5032 4969 4942 4934>,
			<5596 5155 5032 4968 4941 4934>,
			<5630 5167 5032 4965 4937 4930>,
			<5667 5181 5032 4961 4935 4927>,
			<5707 5192 5028 4958 4934 4927>,
			<5751 5204 5024 4955 4934 4927>,
			<5799 5218 5023 4954 4934 4927>,
			<5853 5238 5027 4954 4934 4927>,
			<5913 5262 5033 4954 4934 4928>,
			<5979 5289 5042 4954 4934 4926>,
			<6055 5322 5053 4954 4933 4925>,
			<6151 5366 5067 4955 4934 4925>,
			<6281 5426 5087 4959 4936 4927>,
			<6368 5467 5103 4961 4937 4931>,
			<6461 5504 5108 4962 4941 4935>,
			<6552 5535 5114 4965 4943 4937>,
			<6668 5592 5129 4965 4939 4931>,
			<6824 5657 5140 4964 4938 4930>,
			<7078 5751 5167 4968 4941 4934>,
			<7576 5910 5206 4978 4945 4937>,
			<9319 6190 5288 5004 4965 4951>,
			<9319 6190 5288 5004 4965 4951>,
			<9319 6190 5288 5004 4965 4951>;
	};

};
